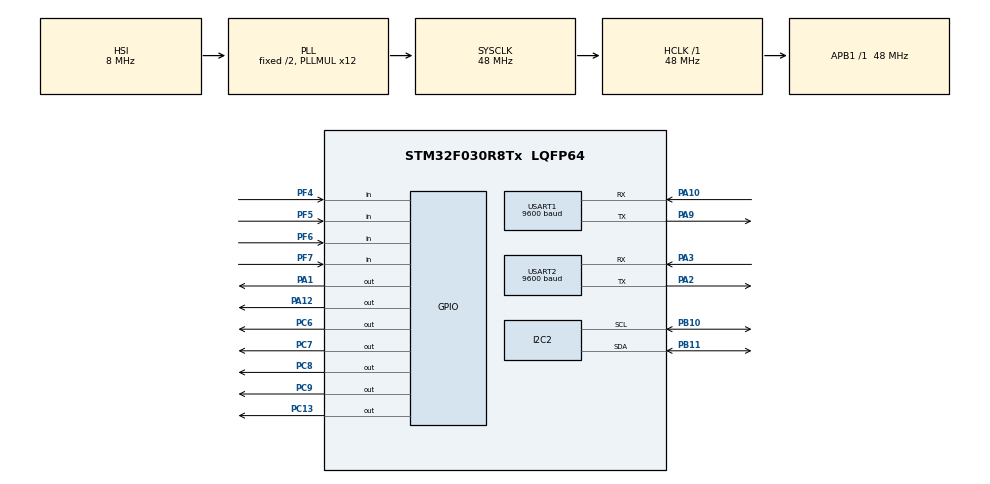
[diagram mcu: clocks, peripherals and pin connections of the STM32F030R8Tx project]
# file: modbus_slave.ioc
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I2C2.Timing=0x10805D88
Mcu.Family=STM32F0
Mcu.Name=STM32F030R8Tx
Mcu.Package=LQFP64
NVIC.TIM17_IRQn=true\:0\:0\:false\:true\:true\:2\:true\:true\:true
NVIC.USART1_IRQn=true\:0\:0\:false\:true\:true\:1\:true\:true\:true
NVIC.USART2_IRQn=true\:0\:0\:false\:false\:true\:true\:true\:true
PA1.Signal=GPIO_Output
PA10.Mode=Asynchronous
PA10.Signal=USART1_RX
PA12.GPIO_Speed=GPIO_SPEED_FREQ_HIGH
PA12.PinState=GPIO_PIN_SET
PA12.Signal=GPIO_Output
PA2.Mode=Asynchronous
PA2.Signal=USART2_TX
PA3.Mode=Asynchronous
PA3.Signal=USART2_RX
PA9.Mode=Asynchronous
PA9.Signal=USART1_TX
PB10.Mode=I2C
PB10.Signal=I2C2_SCL
PB11.Mode=I2C
PB11.Signal=I2C2_SDA
PC13.Signal=GPIO_Output
PC6.Signal=GPIO_Output
PC7.Signal=GPIO_Output
PC8.Signal=GPIO_Output
PC9.Signal=GPIO_Output
PF4.Signal=GPIO_Input
PF5.Signal=GPIO_Input
PF6.Signal=GPIO_Input
PF7.Signal=GPIO_Input
ProjectManager.HeapSize=0x200
ProjectManager.StackSize=0x400
ProjectManager.TargetToolchain=STM32CubeIDE
RCC.AHBFreq_Value=48000000
RCC.APB1Freq_Value=48000000
RCC.APB1TimFreq_Value=48000000
RCC.HCLKFreq_Value=48000000
RCC.PLLMUL=RCC_PLL_MUL12
RCC.RTCClockSelection=RCC_RTCCLKSOURCE_LSE
RCC.SYSCLKFreq_VALUE=48000000
RCC.SYSCLKSource=RCC_SYSCLKSOURCE_PLLCLK
TIM17.Period=1500
TIM17.Prescaler=100
USART1.BaudRate=9600
USART1.DMADisableonRxErrorParam=ADVFEATURE_DMA_DISABLEONRXERROR
USART1.OverrunDisableParam=ADVFEATURE_OVERRUN_DISABLE
USART1.TxPinLevelInvertParam=ADVFEATURE_TXINV_ENABLE
USART1.VirtualMode-Asynchronous=VM_ASYNC
USART2.BaudRate=9600
USART2.DMADisableonRxErrorParam=ADVFEATURE_DMA_DISABLEONRXERROR
USART2.OverrunDisableParam=ADVFEATURE_OVERRUN_DISABLE
USART2.TxPinLevelInvertParam=ADVFEATURE_TXINV_ENABLE
USART2.VirtualMode-Asynchronous=VM_ASYNC
VP_TIM17_VS_ClockSourceINT.Mode=Enable_Timer
board=custom

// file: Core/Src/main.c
/* USER CODE BEGIN Header */
/**
  ******************************************************************************
  * @file           : main.c
  * @brief          : Main program body
  ******************************************************************************
  * @attention
  *
  * Copyright (c) 2025 STMicroelectronics.
  * All rights reserved.
  *
  * This software is licensed under terms that can be found in the LICENSE file
  * in the root directory of this software component.
  * If no LICENSE file comes with this software, it is provided AS-IS.
  *
  ******************************************************************************
  */
/* USER CODE END Header */
#include "main.h"

/* USER CODE BEGIN Includes */
#include "hal_uart.h"
#include "drv_modbus_slave.h"
#include "drv_modbus_slave_valid.h"

/* USER CODE END Includes */

I2C_HandleTypeDef hi2c2;

TIM_HandleTypeDef htim17;

UART_HandleTypeDef huart1;
UART_HandleTypeDef huart2;

void SystemClock_Config(void);
static void MX_GPIO_Init(void);
static void MX_USART1_UART_Init(void);
static void MX_TIM17_Init(void);
static void MX_I2C2_Init(void);
static void MX_USART2_UART_Init(void);
static void MX_NVIC_Init(void);

/* USER CODE BEGIN 0 */
uint8_t rx_buff[10];
uint8_t rx_buff2[10];

/* USER CODE END 0 */

int main(void)
{

  /* USER CODE BEGIN 1 */
	volatile uint32_t u32_cpt2=0;

  /* USER CODE END 1 */

  /* MCU Configuration--------------------------------------------------------*/

  /* Reset of all peripherals, Initializes the Flash interface and the Systick. */
  HAL_Init();

  /* Configure the system clock */
  SystemClock_Config();

  /* Initialize all configured peripherals */
  MX_GPIO_Init();
  MX_USART1_UART_Init();
  MX_TIM17_Init();
  MX_I2C2_Init();
  MX_USART2_UART_Init();

  /* Initialize interrupts */
  MX_NVIC_Init();
  /* USER CODE BEGIN 2 */
  hal_uart_USART1_init ();
  app_modbus_init ();

  HAL_UART_Receive_IT(&huart1, rx_buff, 10);
  HAL_UART_Receive_IT(&huart2, rx_buff2, 10);

  /* USER CODE END 2 */

  /* Infinite loop */
  while (1)
  {

    /* USER CODE BEGIN 3 */

	  for ( volatile uint32_t u32_cpt=0 ; u32_cpt<0x1f ; u32_cpt++){}
	  app_modbus_autom ();

  }
  /* USER CODE END 3 */
}

void SystemClock_Config(void)
{
  RCC_OscInitTypeDef RCC_OscInitStruct = {0};
  RCC_ClkInitTypeDef RCC_ClkInitStruct = {0};
  RCC_PeriphCLKInitTypeDef PeriphClkInit = {0};

  /** Initializes the RCC Oscillators according to the specified parameters
  * in the RCC_OscInitTypeDef structure.
  */
  RCC_OscInitStruct.OscillatorType = RCC_OSCILLATORTYPE_HSI;
  RCC_OscInitStruct.HSIState = RCC_HSI_ON;
  RCC_OscInitStruct.HSICalibrationValue = RCC_HSICALIBRATION_DEFAULT;
  RCC_OscInitStruct.PLL.PLLState = RCC_PLL_ON;
  RCC_OscInitStruct.PLL.PLLSource = RCC_PLLSOURCE_HSI;
  RCC_OscInitStruct.PLL.PLLMUL = RCC_PLL_MUL12;
  RCC_OscInitStruct.PLL.PREDIV = RCC_PREDIV_DIV1;
  if (HAL_RCC_OscConfig(&RCC_OscInitStruct) != HAL_OK)
  {
    Error_Handler();
  }

  /** Initializes the CPU, AHB and APB buses clocks
  */
  RCC_ClkInitStruct.ClockType = RCC_CLOCKTYPE_HCLK|RCC_CLOCKTYPE_SYSCLK
                              |RCC_CLOCKTYPE_PCLK1;
  RCC_ClkInitStruct.SYSCLKSource = RCC_SYSCLKSOURCE_PLLCLK;
  RCC_ClkInitStruct.AHBCLKDivider = RCC_SYSCLK_DIV1;
  RCC_ClkInitStruct.APB1CLKDivider = RCC_HCLK_DIV1;

  if (HAL_RCC_ClockConfig(&RCC_ClkInitStruct, FLASH_LATENCY_1) != HAL_OK)
  {
    Error_Handler();
  }
  PeriphClkInit.PeriphClockSelection = RCC_PERIPHCLK_USART1;
  PeriphClkInit.Usart1ClockSelection = RCC_USART1CLKSOURCE_PCLK1;
  if (HAL_RCCEx_PeriphCLKConfig(&PeriphClkInit) != HAL_OK)
  {
    Error_Handler();
  }
}

/**
  * @brief NVIC Configuration.
  * @retval None
  */
static void MX_NVIC_Init(void)
{
  /* USART1_IRQn interrupt configuration */
  HAL_NVIC_SetPriority(USART1_IRQn, 0, 0);
  HAL_NVIC_EnableIRQ(USART1_IRQn);
  /* TIM17_IRQn interrupt configuration */
  HAL_NVIC_SetPriority(TIM17_IRQn, 0, 0);
  HAL_NVIC_EnableIRQ(TIM17_IRQn);
}

static void MX_I2C2_Init(void)
{

  hi2c2.Instance = I2C2;
  hi2c2.Init.Timing = 0x10805D88;
  hi2c2.Init.OwnAddress1 = 0;
  hi2c2.Init.AddressingMode = I2C_ADDRESSINGMODE_7BIT;
  hi2c2.Init.DualAddressMode = I2C_DUALADDRESS_DISABLE;
  hi2c2.Init.OwnAddress2 = 0;
  hi2c2.Init.OwnAddress2Masks = I2C_OA2_NOMASK;
  hi2c2.Init.GeneralCallMode = I2C_GENERALCALL_DISABLE;
  hi2c2.Init.NoStretchMode = I2C_NOSTRETCH_DISABLE;
  if (HAL_I2C_Init(&hi2c2) != HAL_OK)
  {
    Error_Handler();
  }

  /** Configure Analogue filter
  */
  if (HAL_I2CEx_ConfigAnalogFilter(&hi2c2, I2C_ANALOGFILTER_ENABLE) != HAL_OK)
  {
    Error_Handler();
  }

  /** Configure Digital filter
  */
  if (HAL_I2CEx_ConfigDigitalFilter(&hi2c2, 0) != HAL_OK)
  {
    Error_Handler();
  }

}

static void MX_TIM17_Init(void)
{

  htim17.Instance = TIM17;
  htim17.Init.Prescaler = 100;
  htim17.Init.CounterMode = TIM_COUNTERMODE_UP;
  htim17.Init.Period = 1500;
  htim17.Init.ClockDivision = TIM_CLOCKDIVISION_DIV1;
  htim17.Init.RepetitionCounter = 0;
  htim17.Init.AutoReloadPreload = TIM_AUTORELOAD_PRELOAD_DISABLE;
  if (HAL_TIM_Base_Init(&htim17) != HAL_OK)
  {
    Error_Handler();
  }

}

static void MX_USART1_UART_Init(void)
{

  huart1.Instance = USART1;
  huart1.Init.BaudRate = 9600;
  huart1.Init.WordLength = UART_WORDLENGTH_8B;
  huart1.Init.StopBits = UART_STOPBITS_1;
  huart1.Init.Parity = UART_PARITY_NONE;
  huart1.Init.Mode = UART_MODE_TX_RX;
  huart1.Init.HwFlowCtl = UART_HWCONTROL_NONE;
  huart1.Init.OverSampling = UART_OVERSAMPLING_16;
  huart1.Init.OneBitSampling = UART_ONE_BIT_SAMPLE_DISABLE;
  huart1.AdvancedInit.AdvFeatureInit = UART_ADVFEATURE_TXINVERT_INIT|UART_ADVFEATURE_RXOVERRUNDISABLE_INIT
                              |UART_ADVFEATURE_DMADISABLEONERROR_INIT;
  huart1.AdvancedInit.TxPinLevelInvert = UART_ADVFEATURE_TXINV_ENABLE;
  huart1.AdvancedInit.OverrunDisable = UART_ADVFEATURE_OVERRUN_DISABLE;
  huart1.AdvancedInit.DMADisableonRxError = UART_ADVFEATURE_DMA_DISABLEONRXERROR;
  if (HAL_UART_Init(&huart1) != HAL_OK)
  {
    Error_Handler();
  }

}

static void MX_USART2_UART_Init(void)
{

  huart2.Instance = USART2;
  huart2.Init.BaudRate = 9600;
  huart2.Init.WordLength = UART_WORDLENGTH_8B;
  huart2.Init.StopBits = UART_STOPBITS_1;
  huart2.Init.Parity = UART_PARITY_NONE;
  huart2.Init.Mode = UART_MODE_TX_RX;
  huart2.Init.HwFlowCtl = UART_HWCONTROL_NONE;
  huart2.Init.OverSampling = UART_OVERSAMPLING_16;
  huart2.Init.OneBitSampling = UART_ONE_BIT_SAMPLE_DISABLE;
  huart2.AdvancedInit.AdvFeatureInit = UART_ADVFEATURE_TXINVERT_INIT|UART_ADVFEATURE_RXOVERRUNDISABLE_INIT
                              |UART_ADVFEATURE_DMADISABLEONERROR_INIT;
  huart2.AdvancedInit.TxPinLevelInvert = UART_ADVFEATURE_TXINV_ENABLE;
  huart2.AdvancedInit.OverrunDisable = UART_ADVFEATURE_OVERRUN_DISABLE;
  huart2.AdvancedInit.DMADisableonRxError = UART_ADVFEATURE_DMA_DISABLEONRXERROR;
  if (HAL_UART_Init(&huart2) != HAL_OK)
  {
    Error_Handler();
  }

}

static void MX_GPIO_Init(void)
{
  GPIO_InitTypeDef GPIO_InitStruct = {0};

  /* GPIO Ports Clock Enable */
  __HAL_RCC_GPIOC_CLK_ENABLE();
  __HAL_RCC_GPIOA_CLK_ENABLE();
  __HAL_RCC_GPIOF_CLK_ENABLE();
  __HAL_RCC_GPIOB_CLK_ENABLE();

  /*Configure GPIO pin Output Level */
  HAL_GPIO_WritePin(GPIOC, GPIO_PIN_13|GPIO_PIN_6|GPIO_PIN_7|GPIO_PIN_8
                          |GPIO_PIN_9, GPIO_PIN_RESET);

  /*Configure GPIO pin Output Level */
  HAL_GPIO_WritePin(GPIOA, GPIO_PIN_1, GPIO_PIN_RESET);

  /*Configure GPIO pin Output Level */
  HAL_GPIO_WritePin(GPIOA, GPIO_PIN_12, GPIO_PIN_SET);

  /*Configure GPIO pins : PC13 PC6 PC7 PC8
                           PC9 */
  GPIO_InitStruct.Pin = GPIO_PIN_13|GPIO_PIN_6|GPIO_PIN_7|GPIO_PIN_8
                          |GPIO_PIN_9;
  GPIO_InitStruct.Mode = GPIO_MODE_OUTPUT_PP;
  GPIO_InitStruct.Pull = GPIO_NOPULL;
  GPIO_InitStruct.Speed = GPIO_SPEED_FREQ_LOW;
  HAL_GPIO_Init(GPIOC, &GPIO_InitStruct);

  /*Configure GPIO pin : PA1 */
  GPIO_InitStruct.Pin = GPIO_PIN_1;
  GPIO_InitStruct.Mode = GPIO_MODE_OUTPUT_PP;
  GPIO_InitStruct.Pull = GPIO_NOPULL;
  GPIO_InitStruct.Speed = GPIO_SPEED_FREQ_LOW;
  HAL_GPIO_Init(GPIOA, &GPIO_InitStruct);

  /*Configure GPIO pins : PF4 PF5 PF6 PF7 */
  GPIO_InitStruct.Pin = GPIO_PIN_4|GPIO_PIN_5|GPIO_PIN_6|GPIO_PIN_7;
  GPIO_InitStruct.Mode = GPIO_MODE_INPUT;
  GPIO_InitStruct.Pull = GPIO_NOPULL;
  HAL_GPIO_Init(GPIOF, &GPIO_InitStruct);

  /*Configure GPIO pin : PA12 */
  GPIO_InitStruct.Pin = GPIO_PIN_12;
  GPIO_InitStruct.Mode = GPIO_MODE_OUTPUT_PP;
  GPIO_InitStruct.Pull = GPIO_NOPULL;
  GPIO_InitStruct.Speed = GPIO_SPEED_FREQ_HIGH;
  HAL_GPIO_Init(GPIOA, &GPIO_InitStruct);

}

void Error_Handler(void)
{
  __disable_irq();
  while (1)
  {
  }
}
